# S32K324_M7 register map
Vendor: NXP Semiconductors; File version: 1.1
CPU: CM7 r0p1, little endian, MPU, FPU, VTOR, 4 interrupt priority bits
Registers are 32-bit, read-write, reset 0x0 unless marked. A register's access mark holds for its fields unless they carry their own. Offsets are from the block's base; [hi:lo] are bit positions; {n}, {i} and the like mark numbered series; 'fields as' and 'values as' point back to an identical list.

## TEMPSENSE
Base 0x4037C000
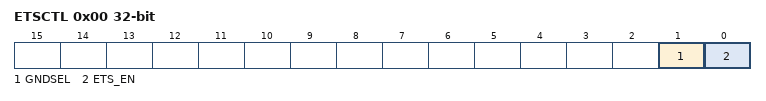
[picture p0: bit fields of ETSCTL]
0x00 ETSCTL — ETS Control
  [1] GNDSEL — Ground selection
    0=No exposure of the ground; 1=Expose ground on the ADC output if ETS_EN=1
  [0] ETS_EN — Temperature Sensor enable
    0=Power down; 1=Functional mode
{0x8+4i} TCA{i} ro reset not defined (i=0..2) — Temperature Coefficient
  [15:0] TCA{i} — Temperature coefficient A{i}

## CRC
Base 0x40380000
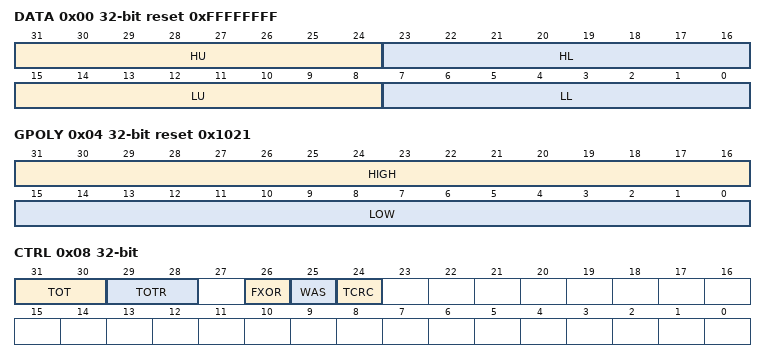
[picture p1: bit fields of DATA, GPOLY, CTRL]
0x00 DATA reset 0xFFFFFFFF — CRC DATA register
  [31:24] HU — CRC High Upper Byte
  [23:16] HL — CRC High Lower Byte
  [15:8] LU — CRC Low Upper Byte
  [7:0] LL — CRC Low Lower Byte
0x04 GPOLY reset 0x1021 — CRC Polynomial register
  [31:16] HIGH — High Polynominal Half-word
  [15:0] LOW — Low Polynominal Half-word
0x08 CTRL — CRC Control register
  [31:30] TOT — Type Of Transpose For Writes
    0=No transposition; 1=Bits in bytes are transposed; bytes are not transposed; 2=Both bits in bytes and bytes are transposed; 3=Only bytes are transposed; no bits in a byte are transposed
  [29:28] TOTR — Type Of Transpose For Read
    values as TOT
  [26] FXOR — Complement Read Of CRC DATA register
    0=No XOR on reading; 1=Invert or complement the read value of the CRC DATA register
  [25] WAS — Write CRC DATA register As Seed
    0=Writes to the CRC DATA register are data values; 1=Writes to the CRC DATA register are seed values
  [24] TCRC
    0=16-bit CRC protocol; 1=32-bit CRC protocol

## JDC
Base 0x40394000
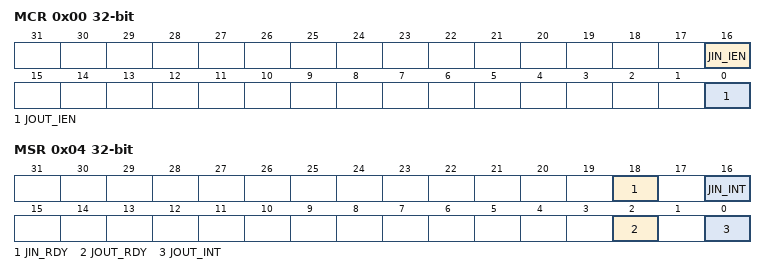
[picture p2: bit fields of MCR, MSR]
0x00 MCR — Module Configuration Register
  [16] JIN_IEN — JIN Interrupt Enable.
    0=Setting MSR[JIN_INT] bit does not assert the JIN interrupt; 1=Setting MSR[JIN_INT] bit asserts the JIN interrupt
  [0] JOUT_IEN — JOUT Interrupt Enable.
    0=Setting MSR[JOUT_INT] bit does not assert the JOUT interrupt; 1=Setting MSR[JOUT_INT] bit asserts the JOUT interrupt
0x04 MSR — Module Status Register
  [18] JIN_RDY ro — JIN Ready (read only).
    0=Cleared upon software read of JIN_IPS contents via IPS; 1=Set when new data is written to the JIN_IPS register
  [16] JIN_INT write-1-clears — JIN Interrupt.
    0=Cleared by writing logic 1; 1=Set when new data is written to the JIN_IPS register
  [2] JOUT_RDY ro — JOUT Ready (read only).
    0=Cleared upon tool read of JOUT register via JTAG port; 1=Set when new data is written to the JOUT_IPS register
  [0] JOUT_INT write-1-clears — JOUT Interrupt.
    0=Cleared by writing logic 1; 1=Set when JOUT_RDY bit is cleared by tool reading JOUT register
0x08 JOUT_IPS — JTAG Output Data Register
  [31:0] Data — JOUT_IPS data.
0x0C JIN_IPS ro — JTAG Input Data Register
  [31:0] Data — JIN_IPS data.

## CONFIGURATION_GPR
Base 0x4039C000
0x1C CONFIG_REG0 ro — General Purpose Configuration 0
  [6] EDB — Hardware Debugger Attached
    0=Debugger not connected; 1=Debugger connected
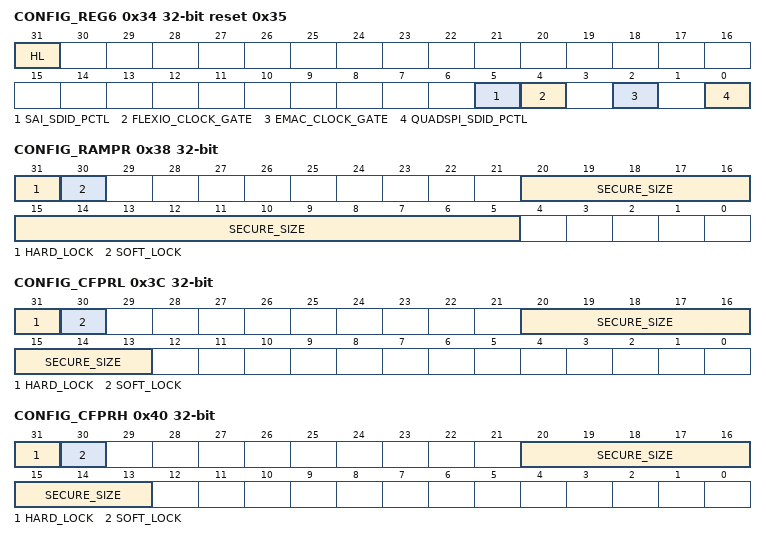
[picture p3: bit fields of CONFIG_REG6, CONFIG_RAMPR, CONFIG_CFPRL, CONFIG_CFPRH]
0x34 CONFIG_REG6 ro reset 0x35 — General Purpose Configuration 6
  [31] HL — Hard Lock
    0=You can write to this register; 1=Register is locked for any write
  [5] SAI_SDID_PCTL — SAI0 and SAI1 clock gating
    0=Clock is off (gated); 1=Clock is on
  [4] FLEXIO_CLOCK_GATE — FlexIO Clock Gating
    0=Clock is off (gated); 1=Clock is on
  [2] EMAC_CLOCK_GATE — Ethernet Clock Gating
    0=Clock is off (gated); 1=Clock is on
  [0] QUADSPI_SDID_PCTL — QuadSPI Clock Gating
    0=Clock is off (gated); 1=Clock is on
0x38 CONFIG_RAMPR ro reset not defined — Configuration RAM Protected Region
  [31] HARD_LOCK
    0=Write access is allowed; 1=Write access is not allowed until next functional reset
  [30] SOFT_LOCK
    0=Write access is allowed; 1=Write access is not allowed
  [20:5] SECURE_SIZE
0x3C CONFIG_CFPRL ro reset not defined — Configuration Code Flash Memory Active Block
  [31] HARD_LOCK
    values as CONFIG_RAMPR.HARD_LOCK
  [30] SOFT_LOCK
    0=Write access is allowed; 1=Write access is not allowed
  [20:13] SECURE_SIZE
0x40 CONFIG_CFPRH ro reset not defined — Configuration Code Flash Memory Passive Block
  fields as CONFIG_CFPRL
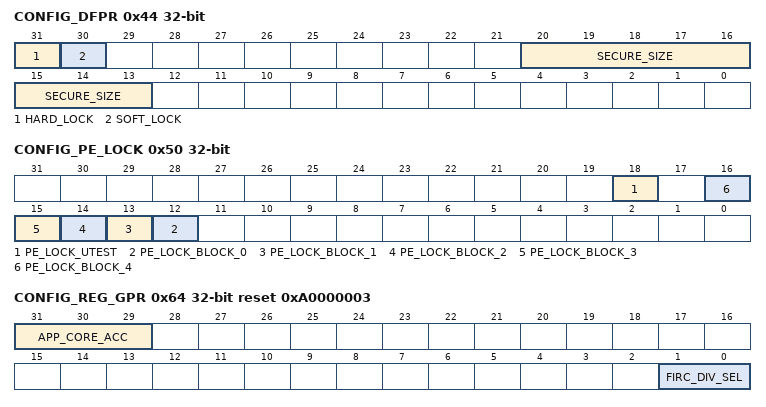
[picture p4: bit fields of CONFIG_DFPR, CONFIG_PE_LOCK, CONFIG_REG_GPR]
0x44 CONFIG_DFPR ro reset not defined — Configuration Data Flash Memory Protected Region
  fields as CONFIG_CFPRL
0x50 CONFIG_PE_LOCK ro — Configuration Program and Erase Lock
  [18] PE_LOCK_UTEST — Program/Erase Lock for UTEST
    0=UTEST lock request is clear; 1=UTEST lock requested
  [n+12] PE_LOCK_BLOCK_{n} (n=0..4) — Program/Erase Lock for Block {n}
    0=Block {n} lock request is clear; 1=Block {n} lock requested
0x54 CONFIG_RAMPR_ALT ro reset not defined — Configuration RAM Protected Region Alternate
  [31:0] INVERT_VALUE_RAMPR
0x58 CONFIG_CFPRL_ALT ro reset not defined — Configuration Code Flash Memory Active Block Alternate
  [31:0] INVERT_VALUE_CFPRAB
0x5C CONFIG_CFPRH_ALT ro reset not defined — Configuration Code Flash Memory Passive Block Alternate
  [31:0] INVERT_VALUE_CFPRP
0x60 CONFIG_DFPR_ALT ro reset not defined — Configuration Data Flash Memory Protected Region Alternate
  [31:0] INVERT_VALUE_DFPR — Invert Value CFPRP
0x64 CONFIG_REG_GPR reset 0xA0000003 — Configuration REG_GPR
  [31:29] APP_CORE_ACC ro — FIRC Divider
    5=Application core can write this field [FIRC_DIV_SEL]
  [1:0] FIRC_DIV_SEL — FIRC Divider
    0=Divided by 2; 1=Divided by 2; 2=Divided by 16; 3=Undivided
